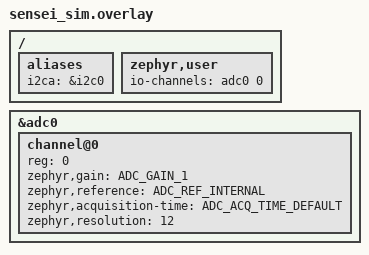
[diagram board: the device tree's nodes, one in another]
/*
 * SPDX-FileCopyrightText: 2026 ETH Zurich and University of Bologna
 * SPDX-License-Identifier: Apache-2.0
 *
 * Authors:
 * - Philip Wiese <wiesep@iis.ee.ethz.ch>
 */

/* Devices that the SENSEI SDK system code (NRF/system/bsp) expects from a board: the I2C bus "i2ca" and
 * the ADC channel of zephyr,user. On native_sim they are the I2C and ADC emulators of the board. */

#include <zephyr/dt-bindings/adc/adc.h>

/ {
	aliases {
		i2ca = &i2c0;
	};

	zephyr,user {
		io-channels = <&adc0 0>;
	};
};

&adc0 {
	#address-cells = <1>;
	#size-cells = <0>;

	channel@0 {
		reg = <0>;
		zephyr,gain = "ADC_GAIN_1";
		zephyr,reference = "ADC_REF_INTERNAL";
		zephyr,acquisition-time = <ADC_ACQ_TIME_DEFAULT>;
		zephyr,resolution = <12>;
	};
};
